# ATtiny1634 device description
Architecture: AVR8; Family: tinyAVR
Registers are 8-bit, access not given, no defined reset value unless marked. A register's access mark holds for its fields unless they carry their own. Offsets are from the block's base; [hi:lo] are bit positions; {n}, {i} and the like mark numbered series.

## LOCKBIT — Lockbits
Instances: LOCKBIT 0 in lockbits
0x00 LOCKBIT
  [1:0] LB — Memory Lock
    0=PROG_VER_DISABLED (Further programming and verification disabled); 2=PROG_DISABLED (Further programming disabled); 3=NO_LOCK (No memory lock features enabled)

## TWI — Two Wire Serial Interface
Instances: TWI 0x00
0x7A TWSD — TWI Slave Data Register
  [7:0] TWSD — TWI slave data bit
0x7B TWSAM — TWI Slave Address Mask Register
0x7C TWSA — TWI Slave Address Register
  [7:0] TWSA — TWI slave address bit
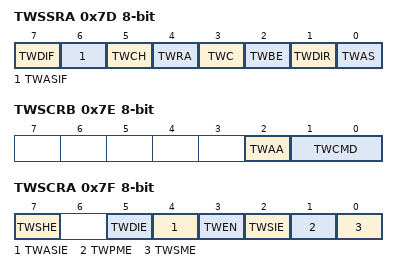
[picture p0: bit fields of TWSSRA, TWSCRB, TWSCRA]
0x7D TWSSRA — TWI Slave Status Register A
  [7] TWDIF — TWI Data Interrupt Flag
  [6] TWASIF — TWI Address/Stop Interrupt Flag
  [5] TWCH — TWI Clock Hold
  [4] TWRA — TWI Receive Acknowledge
  [3] TWC — TWI Collision
  [2] TWBE — TWI Bus Error
  [1] TWDIR — TWI Read/Write Direction
  [0] TWAS — TWI Address or Stop
0x7E TWSCRB — TWI Slave Control Register B
  [2] TWAA — TWI Acknowledge Action
  [1:0] TWCMD
0x7F TWSCRA — TWI Slave Control Register A
  [7] TWSHE — TWI SDA Hold Time Enable
  [5] TWDIE — TWI Data Interrupt Enable
  [4] TWASIE — TWI Address/Stop Interrupt Enable
  [3] TWEN — Two-Wire Interface Enable
  [2] TWSIE — TWI Stop Interrupt Enable
  [1] TWPME — TWI Promiscuous Mode Enable
  [0] TWSME — TWI Smart Mode Enable

## PORTB — I/O Port
Instances: PORTB 0x00
0x2B PINB bits used 3:0 — Port B Data register
0x2C DDRB bits used 3:0 — Data Direction Register, Port B
0x2D PORTB bits used 3:0 — Input Pins, Port B
0x2E PUEB — Pull-up Enable Control Register
  [3:0] PUEB — Pull-up Enable Control bit
0x33 PORTCR — Port Control Register
  [1] BBMB — Break-Before-Make Mode Enable

## PORTC — I/O Port
Instances: PORTC 0x00
0x27 PINC bits used 5:0 — Port C Input Pins
0x28 DDRC bits used 5:0 — Data Direction Register, Port C
0x29 PORTC bits used 5:0 — Port C Data Register
0x2A PUEC — Pull-up Enable Control Register
  [5:0] PUEC — Pull-up Enable Control bit
0x33 PORTCR — Port Control Register
  [2] BBMC — Break-Before-Make Mode Enable

## PORTA — I/O Port
Instances: PORTA 0x00
0x2F PINA — Port A Input Pins
0x30 DDRA — Data Direction Register, Port A
0x31 PORTA — Port A Data Register
0x32 PUEA — Pull-up Enable Control Register
  [7:0] PUEA — Pull-up Enable Control bit
0x33 PORTCR — Port Control Register
  [0] BBMA — Break-Before-Make Mode Enable

## ADC — Analog-to-Digital Converter
Instances: ADC 0x00
0x20 ADC 16-bit — ADC Data Register Bytes
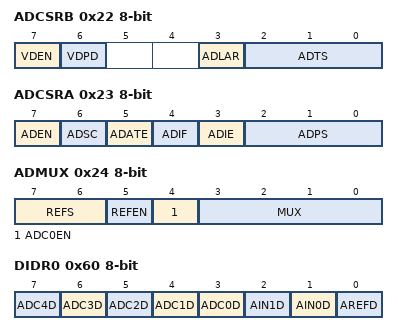
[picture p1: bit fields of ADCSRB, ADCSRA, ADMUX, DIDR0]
0x22 ADCSRB — ADC Control and Status Register B
  [7] VDEN
  [6] VDPD
  [3] ADLAR
  [2:0] ADTS — ADC Auto Trigger Sources
    0=Free Running mode; 1=Analog Comparator; 2=External Interrupt Request 0; 3=Timer/Counter0 Compare Match A; 4=Timer/Counter0 Overflow; 5=Timer/Counter1 Compare Match B; 6=Timer/Counter1 Overflow; 7=Timer/Counter1 Capture Event
0x23 ADCSRA — The ADC Control and Status register
  [7] ADEN — ADC Enable
  [6] ADSC — ADC Start Conversion
  [5] ADATE — ADC Auto Trigger Enable
  [4] ADIF — ADC Interrupt Flag
  [3] ADIE — ADC Interrupt Enable
  [2:0] ADPS — ADC Prescaler Select Bits
    0=2; 1=2; 2=4; 3=8; 4=16; 5=32; 6=64; 7=128
0x24 ADMUX — The ADC multiplexer Selection Register
  [7:6] REFS — Reference Selection Bit
  [5] REFEN
  [4] ADC0EN
  [3:0] MUX — Analog Channel and Gain Selection Bits
0x60 DIDR0 — Digital Input Disable Register 0
  [n+3] ADC{n}D (n=1..4) — ADC{n} Digital input Disable
  [3] ADC0D — ADC0 Digital Input Disable
  [2] AIN1D — AIN1 Digital input Disable
  [1] AIN0D — AIN0 Digital input Disable
  [0] AREFD — AREF Digital input Disable
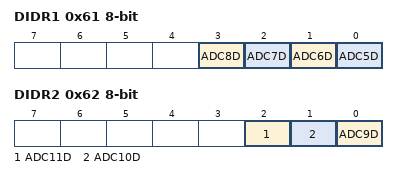
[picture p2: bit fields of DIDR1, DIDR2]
0x61 DIDR1 — Digital Input Disable Register 1
  [3] ADC8D — ADC8 Digital Input Disable
  [2] ADC7D — ADC7 Digital input Disable
  [1] ADC6D — ADC6 Digital input Disable
  [0] ADC5D — ADC5 Digital input Disable
0x62 DIDR2 — Digital Input Disable Register 2
  [2] ADC11D — ADC11 Digital input Disable
  [1] ADC10D — ADC10 Digital input Disable
  [0] ADC9D — ADC9 Digital input Disable
